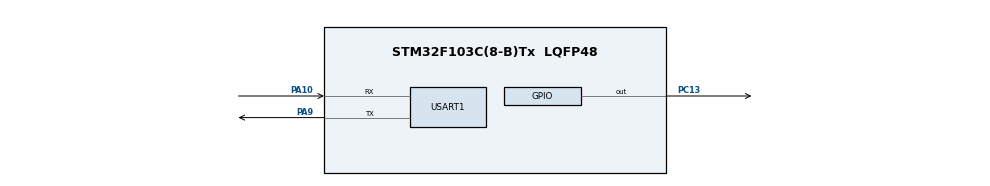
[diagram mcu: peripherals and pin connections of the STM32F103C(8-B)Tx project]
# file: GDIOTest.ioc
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Mcu.Family=STM32F1
Mcu.Name=STM32F103C(8-B)Tx
Mcu.Package=LQFP48
NVIC.PriorityGroup=NVIC_PRIORITYGROUP_4
NVIC.USART1_IRQn=true\:0\:0\:false\:false\:true\:true\:true\:true
PA10.Mode=Asynchronous
PA10.Signal=USART1_RX
PA13.Mode=Serial_Wire
PA13.Signal=SYS_JTMS-SWDIO
PA14.Mode=Serial_Wire
PA14.Signal=SYS_JTCK-SWCLK
PA9.Mode=Asynchronous
PA9.Signal=USART1_TX
PC13-TAMPER-RTC.Signal=GPIO_Output
ProjectManager.HeapSize=0x200
ProjectManager.StackSize=0x400
ProjectManager.TargetToolchain=STM32CubeIDE
RCC.APB1Freq_Value=8000000
RCC.APB2Freq_Value=8000000
USART1.VirtualMode=VM_ASYNC
board=custom

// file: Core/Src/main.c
/* USER CODE BEGIN Header */
/**
 ******************************************************************************
 * @file           : main.c
 * @brief          : Main program body
 ******************************************************************************
 * @attention
 *
 * Copyright (c) 2025 STMicroelectronics.
 * All rights reserved.
 *
 * This software is licensed under terms that can be found in the LICENSE file
 * in the root directory of this software component.
 * If no LICENSE file comes with this software, it is provided AS-IS.
 *
 ******************************************************************************
 */
/* USER CODE END Header */
#include "main.h"

/* USER CODE BEGIN Includes */
#include "log.h"
#include "comm_manager.h"
#include"my_packer.h"
#include <string.h>
/* USER CODE END Includes */

UART_HandleTypeDef huart1;

/* USER CODE BEGIN PV */
static uint32_t now;
static uint32_t total_payload = 0;
static uint32_t total_packet = 0;
static volatile uint8_t receiveByte;
CommManager_t uart1Com;
Packer_t uartPacker = {
		.pack = my_pack_data,
		.unpack = my_unpack_data_state,
};

uint8_t buffer[20];
/* USER CODE END PV */

void SystemClock_Config(void);
static void MX_GPIO_Init(void);
static void MX_USART1_UART_Init(void);

/* USER CODE BEGIN 0 */
void HAL_UART_RxCpltCallback(UART_HandleTypeDef *huart)
{
  if (huart->Instance == USART1)
  {
    onReceiveData(&uart1Com,&receiveByte,1);
//    GPIOC->BSRR = (1 << 13);
    HAL_UART_Receive_IT(&huart1, (uint8_t *)&receiveByte, 1); // doi nhạn doc 1 byte
  }
}

void HAL_UART_TxCpltCallback(UART_HandleTypeDef *huart)
{
  if (huart->Instance == USART1)
  {
    onSendDone(&uart1Com);
  }
}

void u32_to_str(uint32_t value, char *buffer, uint16_t buffer_size)
{
  memset(buffer, 0, buffer_size);
  sprintf(buffer, "%lu", (unsigned long)value);
}

void uart_send(uint8_t *buff, uint16_t length)
{
  HAL_UART_Transmit_IT(&huart1, (const uint8_t *)buff, length);
}

void receive_callback(uint8_t *data, uint16_t length)
{
  total_payload += length;
  total_packet += 1;
  log_printf("nhan duoc %lu byte: total byte %lu\n", total_payload, total_packet);
  u32_to_str(total_payload, (char *)buffer, sizeof(buffer));
  comm_manager_send_data(&uart1Com,data,length);
}

void receive_fail_callback(uint8_t error)
{
  log_println("nhan that bai");
}
/* USER CODE END 0 */

int main(void)
{

  /* MCU Configuration--------------------------------------------------------*/

  /* Reset of all peripherals, Initializes the Flash interface and the Systick. */
  HAL_Init();

  /* Configure the system clock */
  SystemClock_Config();

  /* USER CODE BEGIN SysInit */
  log_init();
  //  uart_manager_init();
  now = HAL_GetTick();
  /* USER CODE END SysInit */

  /* Initialize all configured peripherals */
  MX_GPIO_Init();
  MX_USART1_UART_Init();
  /* USER CODE BEGIN 2 */
//  uart_manager_init(receive_callback, receive_fail_callback, uart_send);
  comm_manager_init(&uart1Com, &uartPacker, receive_callback, receive_fail_callback, uart_send);
  RCC->APB2ENR |= RCC_APB2ENR_IOPCEN | RCC_APB2ENR_IOPBEN;

  // PC13 output push-pull 2MHz
  GPIOC->CRH &= ~(0xF << 20);
  GPIOC->CRH |= (0x2 << 20);

  // PB9 input
  GPIOB->CRH &= ~(0xF << 4); // cLEAR
  GPIOB->CRH |= (0x8 << 4);  // INPUT
  GPIOB->ODR |= (1 << 9);    // PULL up
  HAL_UART_Receive_IT(&huart1, (uint8_t *)&receiveByte, 1);
  log_print("start app\n");
  /* USER CODE END 2 */

  /* Infinite loop */
  while (1)
  {

    /* USER CODE BEGIN 3 */
    //	  if((GPIOB->IDR & (1<<9)) == 0){
    //
    //	  }else{
    //
    //	  }
    //	  GPIOC->BSRR = (1 << (13 + 16)); // LOW → LED ON
    // HAL_Delay(500);
    // GPIOC->BSRR = (1 << 13);        // HIGH → LED OFF
    comm_control(&uart1Com);
  }
  /* USER CODE END 3 */
}

void SystemClock_Config(void)
{
  RCC_OscInitTypeDef RCC_OscInitStruct = {0};
  RCC_ClkInitTypeDef RCC_ClkInitStruct = {0};

  /** Initializes the RCC Oscillators according to the specified parameters
   * in the RCC_OscInitTypeDef structure.
   */
  RCC_OscInitStruct.OscillatorType = RCC_OSCILLATORTYPE_HSI;
  RCC_OscInitStruct.HSIState = RCC_HSI_ON;
  RCC_OscInitStruct.HSICalibrationValue = RCC_HSICALIBRATION_DEFAULT;
  RCC_OscInitStruct.PLL.PLLState = RCC_PLL_NONE;
  if (HAL_RCC_OscConfig(&RCC_OscInitStruct) != HAL_OK)
  {
    Error_Handler();
  }

  /** Initializes the CPU, AHB and APB buses clocks
   */
  RCC_ClkInitStruct.ClockType = RCC_CLOCKTYPE_HCLK | RCC_CLOCKTYPE_SYSCLK | RCC_CLOCKTYPE_PCLK1 | RCC_CLOCKTYPE_PCLK2;
  RCC_ClkInitStruct.SYSCLKSource = RCC_SYSCLKSOURCE_HSI;
  RCC_ClkInitStruct.AHBCLKDivider = RCC_SYSCLK_DIV1;
  RCC_ClkInitStruct.APB1CLKDivider = RCC_HCLK_DIV1;
  RCC_ClkInitStruct.APB2CLKDivider = RCC_HCLK_DIV1;

  if (HAL_RCC_ClockConfig(&RCC_ClkInitStruct, FLASH_LATENCY_0) != HAL_OK)
  {
    Error_Handler();
  }
}

static void MX_USART1_UART_Init(void)
{

  huart1.Instance = USART1;
  huart1.Init.BaudRate = 115200;
  huart1.Init.WordLength = UART_WORDLENGTH_8B;
  huart1.Init.StopBits = UART_STOPBITS_1;
  huart1.Init.Parity = UART_PARITY_NONE;
  huart1.Init.Mode = UART_MODE_TX_RX;
  huart1.Init.HwFlowCtl = UART_HWCONTROL_NONE;
  huart1.Init.OverSampling = UART_OVERSAMPLING_16;
  if (HAL_UART_Init(&huart1) != HAL_OK)
  {
    Error_Handler();
  }
}

static void MX_GPIO_Init(void)
{
  GPIO_InitTypeDef GPIO_InitStruct = {0};

  /* GPIO Ports Clock Enable */
  __HAL_RCC_GPIOC_CLK_ENABLE();
  __HAL_RCC_GPIOA_CLK_ENABLE();

  /*Configure GPIO pin Output Level */
  HAL_GPIO_WritePin(GPIOC, GPIO_PIN_13, GPIO_PIN_RESET);

  /*Configure GPIO pin : PC13 */
  GPIO_InitStruct.Pin = GPIO_PIN_13;
  GPIO_InitStruct.Mode = GPIO_MODE_OUTPUT_PP;
  GPIO_InitStruct.Pull = GPIO_NOPULL;
  GPIO_InitStruct.Speed = GPIO_SPEED_FREQ_LOW;
  HAL_GPIO_Init(GPIOC, &GPIO_InitStruct);

}

void Error_Handler(void)
{
  __disable_irq();
  while (1)
  {
  }
}
